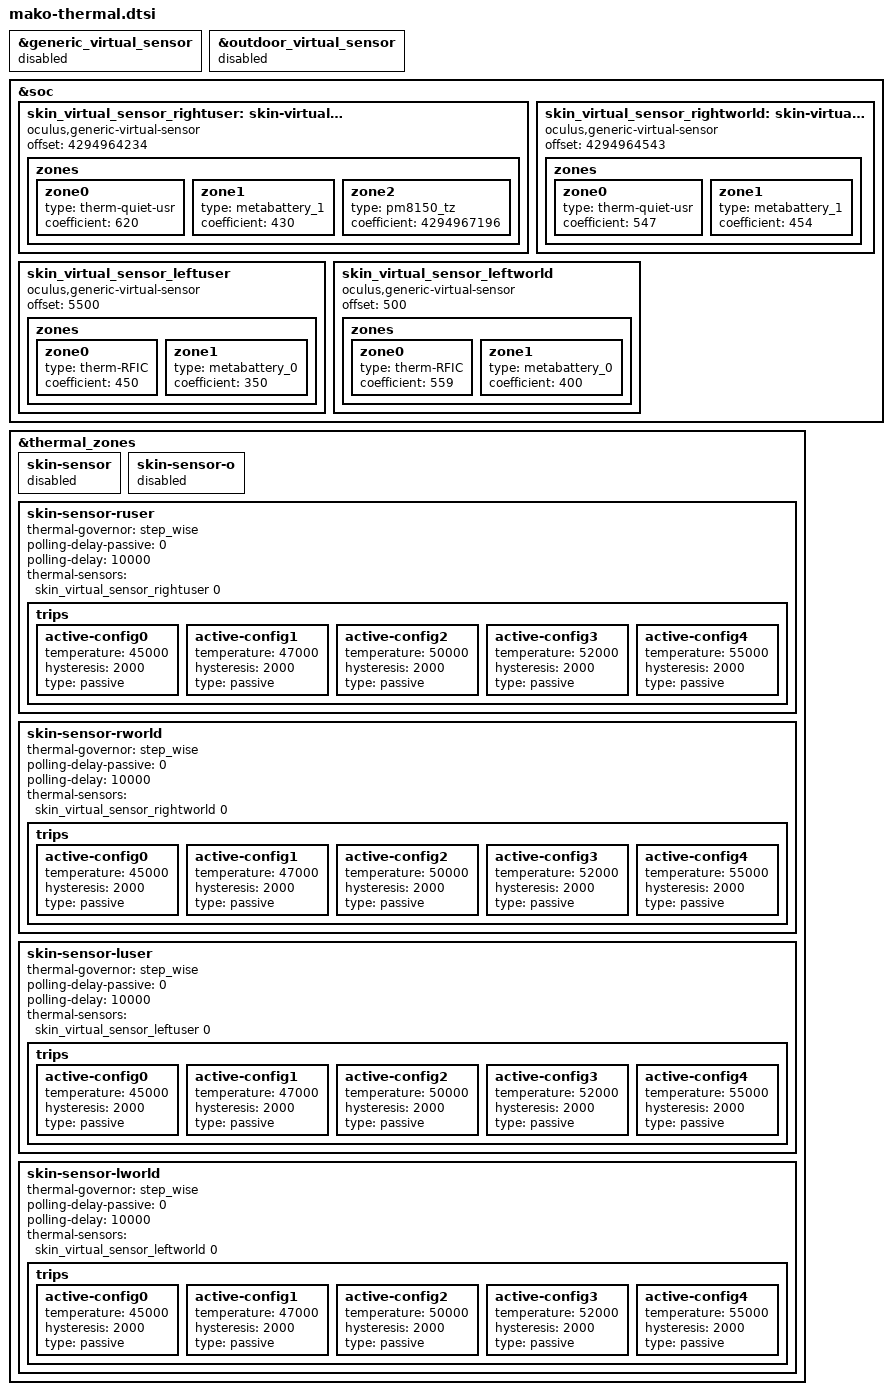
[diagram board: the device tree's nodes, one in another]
&generic_virtual_sensor {
        status = "disabled";
};

&outdoor_virtual_sensor {
	status = "disabled";
};

&soc {
	skin_virtual_sensor_rightuser: skin-virtual-sensor-rightuser {
		compatible = "oculus,generic-virtual-sensor";
		#thermal-sensor-cells = <0>;
		status = "ok";
		// 32 bit 2's complement -3062
		offset = <4294964234>;
		zones {
			zone0 {
				type = "therm-quiet-usr";
				coefficient = <620>;
			};
			zone1 {
				type = "metabattery_1";
				coefficient = <430>;
			};
			zone2 {
				type = "pm8150_tz";
				// 32 bit 2's complement -100
				coefficient = <4294967196>;
			};
		};
	};

	skin_virtual_sensor_rightworld: skin-virtual-sensor-rightworld {
		compatible = "oculus,generic-virtual-sensor";
		#thermal-sensor-cells = <0>;
		status = "ok";
		// 32 bit 2's complement -2753
		offset = <4294964543>;
		zones {
			zone0 {
				type = "therm-quiet-usr";
				coefficient = <547>;
			};
			zone1 {
				type = "metabattery_1";
				coefficient = <454>;
			};
		};
	};

	skin_virtual_sensor_leftuser: skin_virtual_sensor_leftuser {
		compatible = "oculus,generic-virtual-sensor";
		#thermal-sensor-cells = <0>;
		status = "ok";
		offset = <5500>;
		zones {
			zone0 {
				type = "therm-RFIC";
				coefficient = <450>;
			};
			zone1 {
				type = "metabattery_0";
				coefficient = <350>;
			};
		};
	};

	skin_virtual_sensor_leftworld: skin_virtual_sensor_leftworld {
		compatible = "oculus,generic-virtual-sensor";
		#thermal-sensor-cells = <0>;
		status = "ok";
		offset = <500>;
		zones {
			zone0 {
				type = "therm-RFIC";
				coefficient = <559>;
			};
			zone1 {
				type = "metabattery_0";
				coefficient = <400>;
			};
		};
	};
};

&thermal_zones {
	skin-sensor {
		status = "disabled";
	};

	skin-sensor-o {
		status = "disabled";
	};

	skin-sensor-ruser {
		thermal-governor = "step_wise";
		polling-delay-passive = <0>;
		polling-delay = <10000>;
		thermal-sensors = <&skin_virtual_sensor_rightuser 0>;
		trips {
			active-config0 {
				temperature = <45000>;
				hysteresis = <2000>;
				type = "passive";
			};
			active-config1 {
				temperature = <47000>;
				hysteresis = <2000>;
				type = "passive";
			};
			active-config2 {
				temperature = <50000>;
				hysteresis = <2000>;
				type = "passive";
			};
			active-config3 {
				temperature = <52000>;
				hysteresis = <2000>;
				type = "passive";
			};
			active-config4 {
				temperature = <55000>;
				hysteresis = <2000>;
				type = "passive";
			};
		};
	};

	skin-sensor-rworld {
		thermal-governor = "step_wise";
		polling-delay-passive = <0>;
		polling-delay = <10000>;
		thermal-sensors = <&skin_virtual_sensor_rightworld 0>;
		trips {
			active-config0 {
				temperature = <45000>;
				hysteresis = <2000>;
				type = "passive";
			};
			active-config1 {
				temperature = <47000>;
				hysteresis = <2000>;
				type = "passive";
			};
			active-config2 {
				temperature = <50000>;
				hysteresis = <2000>;
				type = "passive";
			};
			active-config3 {
				temperature = <52000>;
				hysteresis = <2000>;
				type = "passive";
			};
			active-config4 {
				temperature = <55000>;
				hysteresis = <2000>;
				type = "passive";
			};
		};
	};

	skin-sensor-luser {
		thermal-governor = "step_wise";
		polling-delay-passive = <0>;
		polling-delay = <10000>;
		thermal-sensors = <&skin_virtual_sensor_leftuser 0>;
		trips {
			active-config0 {
				temperature = <45000>;
				hysteresis = <2000>;
				type = "passive";
			};
			active-config1 {
				temperature = <47000>;
				hysteresis = <2000>;
				type = "passive";
			};
			active-config2 {
				temperature = <50000>;
				hysteresis = <2000>;
				type = "passive";
			};
			active-config3 {
				temperature = <52000>;
				hysteresis = <2000>;
				type = "passive";
			};
			active-config4 {
				temperature = <55000>;
				hysteresis = <2000>;
				type = "passive";
			};
		};
	};

	skin-sensor-lworld {
		thermal-governor = "step_wise";
		polling-delay-passive = <0>;
		polling-delay = <10000>;
		thermal-sensors = <&skin_virtual_sensor_leftworld 0>;
		trips {
			active-config0 {
				temperature = <45000>;
				hysteresis = <2000>;
				type = "passive";
			};
			active-config1 {
				temperature = <47000>;
				hysteresis = <2000>;
				type = "passive";
			};
			active-config2 {
				temperature = <50000>;
				hysteresis = <2000>;
				type = "passive";
			};
			active-config3 {
				temperature = <52000>;
				hysteresis = <2000>;
				type = "passive";
			};
			active-config4 {
				temperature = <55000>;
				hysteresis = <2000>;
				type = "passive";
			};
		};
	};
};
